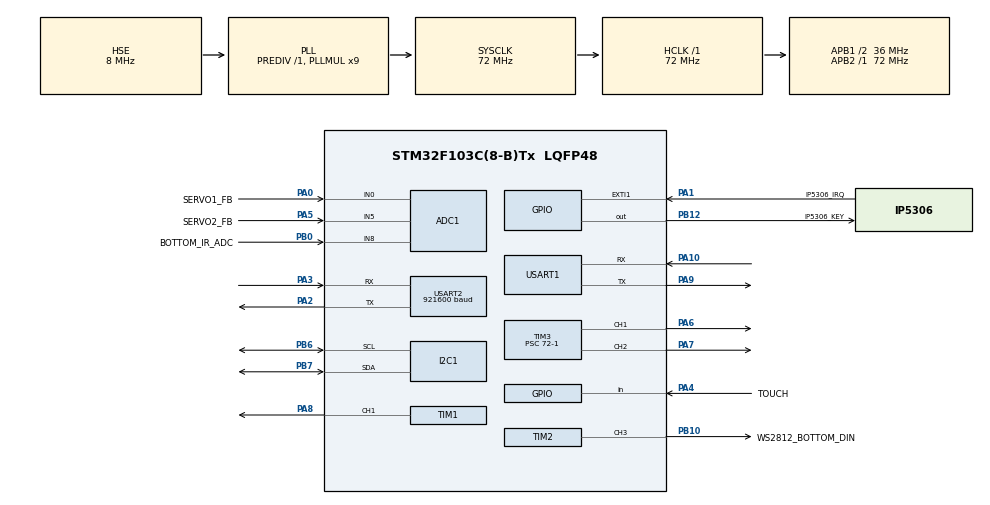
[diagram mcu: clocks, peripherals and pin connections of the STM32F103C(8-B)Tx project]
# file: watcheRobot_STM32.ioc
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ADC1.Channel-0\#ChannelRegularConversion=ADC_CHANNEL_0
ADC1.Channel-1\#ChannelRegularConversion=ADC_CHANNEL_5
ADC1.Channel-2\#ChannelRegularConversion=ADC_CHANNEL_8
ADC1.NbrOfConversion=3
ADC1.NbrOfConversionFlag=1
ADC1.Rank-0\#ChannelRegularConversion=1
ADC1.Rank-1\#ChannelRegularConversion=2
ADC1.Rank-2\#ChannelRegularConversion=3
ADC1.SamplingTime-0\#ChannelRegularConversion=ADC_SAMPLETIME_239CYCLES_5
ADC1.SamplingTime-1\#ChannelRegularConversion=ADC_SAMPLETIME_239CYCLES_5
ADC1.SamplingTime-2\#ChannelRegularConversion=ADC_SAMPLETIME_239CYCLES_5
ADC1.master=1
Dma.Request0=USART1_TX
Dma.Request1=USART2_RX
Dma.Request2=USART2_TX
Dma.Request3=TIM1_CH1
Dma.Request4=TIM2_CH3
Dma.TIM1_CH1.3.Direction=DMA_MEMORY_TO_PERIPH
Dma.TIM1_CH1.3.Instance=DMA1_Channel2
Dma.TIM1_CH1.3.MemDataAlignment=DMA_MDATAALIGN_HALFWORD
Dma.TIM1_CH1.3.MemInc=DMA_MINC_ENABLE
Dma.TIM1_CH1.3.Mode=DMA_NORMAL
Dma.TIM1_CH1.3.PeriphDataAlignment=DMA_PDATAALIGN_HALFWORD
Dma.TIM1_CH1.3.PeriphInc=DMA_PINC_DISABLE
Dma.TIM1_CH1.3.Priority=DMA_PRIORITY_HIGH
Dma.TIM2_CH3.4.Direction=DMA_MEMORY_TO_PERIPH
Dma.TIM2_CH3.4.Instance=DMA1_Channel1
Dma.TIM2_CH3.4.MemDataAlignment=DMA_MDATAALIGN_HALFWORD
Dma.TIM2_CH3.4.MemInc=DMA_MINC_ENABLE
Dma.TIM2_CH3.4.Mode=DMA_NORMAL
Dma.TIM2_CH3.4.PeriphDataAlignment=DMA_PDATAALIGN_HALFWORD
Dma.TIM2_CH3.4.PeriphInc=DMA_PINC_DISABLE
Dma.TIM2_CH3.4.Priority=DMA_PRIORITY_HIGH
Dma.USART1_TX.0.Direction=DMA_MEMORY_TO_PERIPH
Dma.USART1_TX.0.Instance=DMA1_Channel4
Dma.USART1_TX.0.MemDataAlignment=DMA_MDATAALIGN_BYTE
Dma.USART1_TX.0.MemInc=DMA_MINC_ENABLE
Dma.USART1_TX.0.Mode=DMA_NORMAL
Dma.USART1_TX.0.PeriphDataAlignment=DMA_PDATAALIGN_BYTE
Dma.USART1_TX.0.PeriphInc=DMA_PINC_DISABLE
Dma.USART1_TX.0.Priority=DMA_PRIORITY_LOW
Dma.USART2_RX.1.Direction=DMA_PERIPH_TO_MEMORY
Dma.USART2_RX.1.Instance=DMA1_Channel6
Dma.USART2_RX.1.MemDataAlignment=DMA_MDATAALIGN_BYTE
Dma.USART2_RX.1.MemInc=DMA_MINC_ENABLE
Dma.USART2_RX.1.Mode=DMA_NORMAL
Dma.USART2_RX.1.PeriphDataAlignment=DMA_PDATAALIGN_BYTE
Dma.USART2_RX.1.PeriphInc=DMA_PINC_DISABLE
Dma.USART2_RX.1.Priority=DMA_PRIORITY_LOW
Dma.USART2_TX.2.Direction=DMA_MEMORY_TO_PERIPH
Dma.USART2_TX.2.Instance=DMA1_Channel7
Dma.USART2_TX.2.MemDataAlignment=DMA_MDATAALIGN_BYTE
Dma.USART2_TX.2.MemInc=DMA_MINC_ENABLE
Dma.USART2_TX.2.Mode=DMA_NORMAL
Dma.USART2_TX.2.PeriphDataAlignment=DMA_PDATAALIGN_BYTE
Dma.USART2_TX.2.PeriphInc=DMA_PINC_DISABLE
Dma.USART2_TX.2.Priority=DMA_PRIORITY_LOW
I2C1.I2C_Mode=I2C_Fast
Mcu.Family=STM32F1
Mcu.Name=STM32F103C(8-B)Tx
Mcu.Package=LQFP48
NVIC.DMA1_Channel1_IRQn=true\:0\:0\:false\:false\:true\:false\:true\:true
NVIC.DMA1_Channel2_IRQn=true\:0\:0\:false\:false\:true\:false\:true\:true
NVIC.DMA1_Channel4_IRQn=true\:0\:0\:false\:false\:true\:false\:true\:true
NVIC.DMA1_Channel6_IRQn=true\:0\:0\:false\:false\:true\:false\:true\:true
NVIC.DMA1_Channel7_IRQn=true\:0\:0\:false\:false\:true\:false\:true\:true
NVIC.EXTI1_IRQn=true\:5\:0\:true\:false\:true\:true\:true\:true
NVIC.PriorityGroup=NVIC_PRIORITYGROUP_4
NVIC.USART1_IRQn=true\:0\:0\:false\:false\:true\:true\:true\:true
NVIC.USART2_IRQn=true\:0\:0\:false\:false\:true\:true\:true\:true
PA0-WKUP.GPIO_Label=SERVO1_FB
PA0-WKUP.Signal=ADCx_IN0
PA1.GPIO_Label=IP5306_IRQ
PA1.GPIO_ModeDefaultEXTI=GPIO_MODE_IT_RISING
PA1.GPIO_PuPd=GPIO_PULLDOWN
PA1.Signal=GPXTI1
PA10.Mode=Asynchronous
PA10.Signal=USART1_RX
PA13.Mode=Serial_Wire
PA13.Signal=SYS_JTMS-SWDIO
PA14.Mode=Serial_Wire
PA14.Signal=SYS_JTCK-SWCLK
PA2.Mode=Asynchronous
PA2.Signal=USART2_TX
PA3.GPIO_PuPd=GPIO_PULLUP
PA3.Mode=Asynchronous
PA3.Signal=USART2_RX
PA4.GPIO_Label=TOUCH
PA4.GPIO_Mode=GPIO_MODE_INPUT
PA4.GPIO_PuPd=GPIO_PULLUP
PA4.Signal=GPIO_Input
PA5.GPIO_Label=SERVO2_FB
PA5.Signal=ADCx_IN5
PA6.Signal=S_TIM3_CH1
PA7.Signal=S_TIM3_CH2
PA8.GPIO_Speed=GPIO_SPEED_FREQ_HIGH
PA8.Signal=S_TIM1_CH1
PA9.Mode=Asynchronous
PA9.Signal=USART1_TX
PB0.GPIO_Label=BOTTOM_IR_ADC
PB0.Signal=ADCx_IN8
PB10.GPIO_Label=WS2812_BOTTOM_DIN
PB10.GPIO_Speed=GPIO_SPEED_FREQ_HIGH
PB10.Signal=S_TIM2_CH3
PB12.GPIO_Label=IP5306_KEY
PB12.GPIO_ModeDefaultOutputPP=GPIO_MODE_OUTPUT_PP
PB12.GPIO_PuPd=GPIO_NOPULL
PB12.PinState=GPIO_PIN_RESET
PB12.Signal=GPIO_Output
PB6.Mode=I2C
PB6.Signal=I2C1_SCL
PB7.Mode=I2C
PB7.Signal=I2C1_SDA
PD0-OSC_IN.Mode=HSE-External-Oscillator
PD0-OSC_IN.Signal=RCC_OSC_IN
PD1-OSC_OUT.Mode=HSE-External-Oscillator
PD1-OSC_OUT.Signal=RCC_OSC_OUT
ProjectManager.HeapSize=0x200
ProjectManager.StackSize=0x400
ProjectManager.TargetToolchain=CMake
RCC.ADCPresc=RCC_ADCPCLK2_DIV6
RCC.AHBFreq_Value=72000000
RCC.APB1CLKDivider=RCC_HCLK_DIV2
RCC.APB1Freq_Value=36000000
RCC.APB1TimFreq_Value=72000000
RCC.APB2Freq_Value=72000000
RCC.APB2TimFreq_Value=72000000
RCC.HCLKFreq_Value=72000000
RCC.PLLMUL=RCC_PLL_MUL9
RCC.PLLSourceVirtual=RCC_PLLSOURCE_HSE
RCC.SYSCLKFreq_VALUE=72000000
RCC.SYSCLKSource=RCC_SYSCLKSOURCE_PLLCLK
RCC.USBFreq_Value=72000000
SH.ADCx_IN0.0=ADC1_IN0,IN0
SH.ADCx_IN5.0=ADC1_IN5,IN5
SH.ADCx_IN8.0=ADC1_IN8,IN8
SH.S_TIM1_CH1.0=TIM1_CH1,PWM Generation1 CH1
SH.S_TIM2_CH3.0=TIM2_CH3,PWM Generation3 CH3
SH.S_TIM3_CH1.0=TIM3_CH1,PWM Generation1 CH1
SH.S_TIM3_CH2.0=TIM3_CH2,PWM Generation2 CH2
TIM1.Channel-PWM\ Generation1\ CH1=TIM_CHANNEL_1
TIM1.Period=89
TIM2.Channel-PWM\ Generation3\ CH3=TIM_CHANNEL_3
TIM2.Period=89
TIM3.Channel-PWM\ Generation1\ CH1=TIM_CHANNEL_1
TIM3.Channel-PWM\ Generation2\ CH2=TIM_CHANNEL_2
TIM3.Period=19999
TIM3.Prescaler=72-1
TIM3.Pulse-PWM\ Generation1\ CH1=1500
TIM3.Pulse-PWM\ Generation2\ CH2=1500
USART1.VirtualMode=VM_ASYNC
USART2.BaudRate=921600
USART2.VirtualMode=VM_ASYNC
board=custom

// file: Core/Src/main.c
/* USER CODE BEGIN Header */
/**
  ******************************************************************************
  * @file           : main.c
  * @brief          : Main program body
  ******************************************************************************
  * @attention
  *
  * Copyright (c) 2026 STMicroelectronics.
  * All rights reserved.
  *
  * This software is licensed under terms that can be found in the LICENSE file
  * in the root directory of this software component.
  * If no LICENSE file comes with this software, it is provided AS-IS.
  *
  ******************************************************************************
  */
/* USER CODE END Header */
#include "main.h"
#include "adc.h"
#include "dma.h"
#include "i2c.h"
#include "tim.h"
#include "usart.h"
#include "gpio.h"

/* USER CODE BEGIN Includes */
#include "app.h"
/* USER CODE END Includes */

void SystemClock_Config(void);

int main(void)
{

  /* MCU Configuration--------------------------------------------------------*/

  /* Reset of all peripherals, Initializes the Flash interface and the Systick. */
  HAL_Init();

  /* Configure the system clock */
  SystemClock_Config();

  /* Initialize all configured peripherals */
  MX_GPIO_Init();
  MX_DMA_Init();
  MX_USART1_UART_Init();
  MX_TIM3_Init();
  MX_I2C1_Init();
  MX_USART2_UART_Init();
  MX_TIM1_Init();
  MX_ADC1_Init();
  MX_TIM2_Init();
  /* USER CODE BEGIN 2 */
  App_Init();
  /* USER CODE END 2 */

  /* Infinite loop */
  while (1)
  {

    /* USER CODE BEGIN 3 */
    App_RunOnce();
  }
  /* USER CODE END 3 */
}

void SystemClock_Config(void)
{
  RCC_OscInitTypeDef RCC_OscInitStruct = {0};
  RCC_ClkInitTypeDef RCC_ClkInitStruct = {0};
  RCC_PeriphCLKInitTypeDef PeriphClkInit = {0};

  /** Initializes the RCC Oscillators according to the specified parameters
  * in the RCC_OscInitTypeDef structure.
  */
  RCC_OscInitStruct.OscillatorType = RCC_OSCILLATORTYPE_HSE;
  RCC_OscInitStruct.HSEState = RCC_HSE_ON;
  RCC_OscInitStruct.HSEPredivValue = RCC_HSE_PREDIV_DIV1;
  RCC_OscInitStruct.HSIState = RCC_HSI_ON;
  RCC_OscInitStruct.PLL.PLLState = RCC_PLL_ON;
  RCC_OscInitStruct.PLL.PLLSource = RCC_PLLSOURCE_HSE;
  RCC_OscInitStruct.PLL.PLLMUL = RCC_PLL_MUL9;
  if (HAL_RCC_OscConfig(&RCC_OscInitStruct) != HAL_OK)
  {
    Error_Handler();
  }

  /** Initializes the CPU, AHB and APB buses clocks
  */
  RCC_ClkInitStruct.ClockType = RCC_CLOCKTYPE_HCLK|RCC_CLOCKTYPE_SYSCLK
                              |RCC_CLOCKTYPE_PCLK1|RCC_CLOCKTYPE_PCLK2;
  RCC_ClkInitStruct.SYSCLKSource = RCC_SYSCLKSOURCE_PLLCLK;
  RCC_ClkInitStruct.AHBCLKDivider = RCC_SYSCLK_DIV1;
  RCC_ClkInitStruct.APB1CLKDivider = RCC_HCLK_DIV2;
  RCC_ClkInitStruct.APB2CLKDivider = RCC_HCLK_DIV1;

  if (HAL_RCC_ClockConfig(&RCC_ClkInitStruct, FLASH_LATENCY_2) != HAL_OK)
  {
    Error_Handler();
  }
  PeriphClkInit.PeriphClockSelection = RCC_PERIPHCLK_ADC;
  PeriphClkInit.AdcClockSelection = RCC_ADCPCLK2_DIV6;
  if (HAL_RCCEx_PeriphCLKConfig(&PeriphClkInit) != HAL_OK)
  {
    Error_Handler();
  }
}

void Error_Handler(void)
{
  __disable_irq();
  while (1)
  {
  }
}
